# RT584ZCM33 register map
Series: ARMv8-M Mainline; File version: 1.0
CPU: CM33 r0p0, little endian, MPU, no FPU, VTOR, 3 interrupt priority bits
Registers are 32-bit, read-write, reset 0x0 unless marked. A register's access mark holds for its fields unless they carry their own. Offsets are from the block's base; [hi:lo] are bit positions.

## TIMER32K0_Non-Secure — TIMER32K0 Non-Secure Register block
Base 0x4000D000
Same registers: TIMER32K1_Non-Secure 0x4000E000, TIMER32K0_Secure 0x5000D000, TIMER32K1_Secure 0x5000E000
0x00 T3_LOAD_REG — The timer initial value. Timer update the down initial value after write this register. This register also the timer repeated value in periodic mode.
0x04 T3_VALUE_REG ro — The timer current value. This value is from timerClk domain synchronized to PCLK domain.
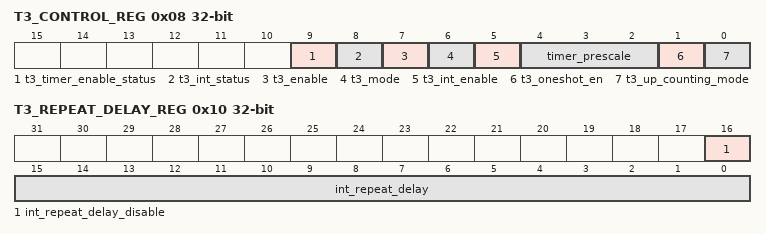
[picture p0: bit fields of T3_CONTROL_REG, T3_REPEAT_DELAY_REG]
0x08 T3_CONTROL_REG — t3 control
  [9] t3_timer_enable_status ro — timer enable status at timer clk domain
    0=B_9 (timer enable status at timer clk domain)
  [8] t3_int_status ro — timer interupt status
    0=B_8 (timer interupt status)
  [7] t3_enable — timer enable; one shot mode trigger 0:disable 1:enable
    0=B_7_ITEM0 (disable); 1=B_7_ITEM1 (enable)
  [6] t3_mode — timer mode select 0:free running mode 1:periodic mode
    0=B_6_ITEM0 (free running mode); 1=B_6_ITEM1 (periodic mode)
  [5] t3_int_enable — timer interupt enable 0:disable 1:enable
    0=B_5_ITEM0 (disable); 1=B_5_ITEM1 (enable)
  [4:2] timer_prescale — 0: timer clock is divided by 1 1: timer clock is divided by 16 2: timer clock is divided by 256 3: timer clock is divided by 2 4: timer clock is divided by 8 5: timer clock is divided by 32 6: timer clock is divided by 128 7: timer clock is divided by 1024 only valid when prescale_val=0
    0=B_2_to_4_ITEM0 (timer clock is divided by 1); 1=B_2_to_4_ITEM1 (timer clock is divided by 16); 2=B_2_to_4_ITEM2 (timer clock is divided by 256); 3=B_2_to_4_ITEM3 (timer clock is divided by 2); 4=B_2_to_4_ITEM4 (timer clock is divided by 8); 5=B_2_to_4_ITEM5 (timer clock is divided by 32); 6=B_2_to_4_ITEM6 (timer clock is divided by 128); 7=B_2_to_4_ITEM7 (timer clock is divided by 1024)
  [1] t3_oneshot_en — timer one shot mode enable 0: one shot mode disable 1: one shot mode enable
    0=B_1_ITEM0 (one shot mode disable); 1=B_1_ITEM1 (one shot mode enable)
  [0] t3_up_counting_mode — timer up counting mode enable 0: down counting mode 1: up counting mode
    0=B_0_ITEM0 (down counting mode); 1=B_0_ITEM1 (up counting mode)
0x0C T3_CLEAR_REG wo — Write any value to clear timer interupt status
0x10 T3_REPEAT_DELAY_REG — t3 repeat delay
  [16] int_repeat_delay_disable — timer interupt repeat delay function disable 0:enable 1:disable int_repeat_delay
    0=B_16 (timer interupt repeat delay function disable 0:enable 1:disable int_repeat_delay)
  [15:0] int_repeat_delay — timer interupt repeat delay for times, for sleep mode only
0x14 T3_PRESCALE_REG — t3 prescale
  [9:0] timer3_prescale — timer clock is divided by prescale+1, only valid when>0
0x18 T3_EX_VAL_REG — timer expired value

## WDT_Non-Secure — WDT Non-Secure Register block
Base 0x40010000
Same registers: WDT_Secure 0x50010000
0x00 WIN_MAX_REG — The watchdog window maximum value, and also reload this value when have a specific write to "Kick" register
0x04 VALUE_REG ro — The timer current value. This value is from timerClk domain synchronized to PCLK domain.
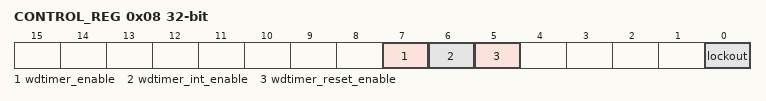
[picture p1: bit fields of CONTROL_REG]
0x08 CONTROL_REG — control
  [7] wdtimer_enable — Wdtimer enable 0:disable 1:enable
    0=B_7_ITEM0 (disable); 1=B_7_ITEM1 (enable)
  [6] wdtimer_int_enable — Wdtimer interupt enable 0:disable 1:enable
    0=B_6_ITEM0 (disable); 1=B_6_ITEM1 (enable)
  [5] wdtimer_reset_enable — WDtimer reset enable 0:disable 1:enable
    0=B_5_ITEM0 (disable); 1=B_5_ITEM1 (enable)
  [0] lockout — watch dog timer lock 0: unlock 1: lock when locked, windowMax, control,Timer reset ocurr clear, Timer interupt, windowMin can't be changed
    0=B_0_ITEM0 (unlock); 1=B_0_ITEM1 (lock)
0x0C KICK_REG wo — WatchDog timer kick reg, write this reg with specific value 0xa5a5 to kick and reload the watchdog timer
0x10 RESET_OCCUR_REG — reset occur
  [7:0] reset_occur — reset occur counter, write any value to clear the reset occur counter. Read this register to read current reset occur value
    0=B_0_to_7 (reset occur counter, write any value to clear the reset occur counter. Read this register to read current reset occur value)
0x14 CLEAR_REG — write any value to clear the Wdtimer interupt
0x18 INT_VALUE_REG — timer interupt value, set to send warning interupt when interupt value is meet
0x1C WIN_MIN_REG — If windowMin=0 or windowMin > windowMax this feature is unused. Window minimum value to prevent kick too frequently.
0x20 PRESCALE_REG — prescale
  [11:0] wdt_prescale_val — timer clock is divided by prescale_val+1
